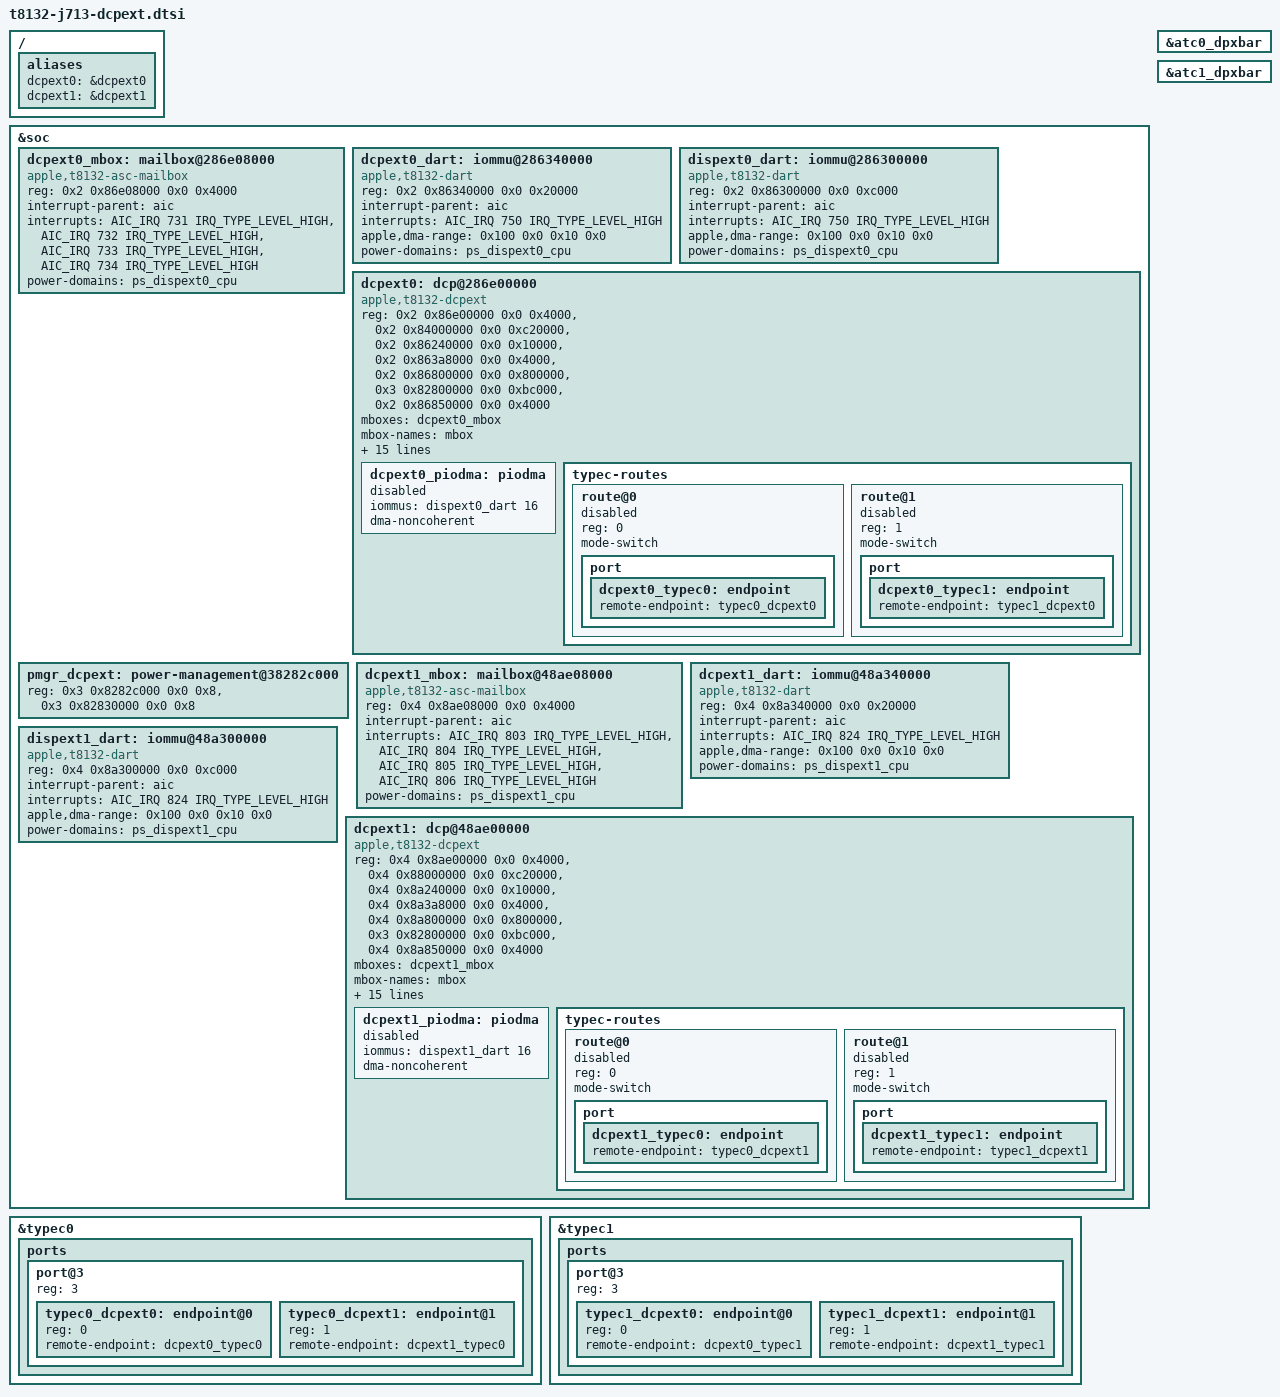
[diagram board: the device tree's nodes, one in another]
// SPDX-License-Identifier: GPL-2.0+ OR MIT
/*
 * Apple MacBook Air (13-inch, M4) external display coprocessors (DCP-ext).
 *
 * T8132 has two external display pipes, dispext0 and dispext1, each with
 * its own DCP, mailbox, DCP DART and display DART. They mirror the
 * internal display (t8132-j713-display.dtsi) at other bases and share its
 * firmware clock window (disp-4), which also holds their realtime bandwidth
 * request slots in the PMC.
 *
 * iBoot starts both and leaves them quiesced, as it does the internal one.
 * When the boot loader hands them over (opt-in, and only after the internal
 * display was handed over), it reserves their firmware memory, publishes
 * its UUID and version and marks each node
 * apple,t8132-dcpext-firmware-ready. The DCP driver adopts only a marked
 * coprocessor, and the DART driver leaves its firmware and display DARTs
 * untouched otherwise. PIODMA is enabled at runtime once the display DART
 * is adopted.
 *
 * Streams: SID23 for the firmware, SID0 scanout and SID16 PIODMA, as on
 * the internal display.
 *
 * Copyright The Asahi Linux Contributors
 */

/ {
	aliases {
		dcpext0 = &dcpext0;
		dcpext1 = &dcpext1;
	};
};

&soc {
	dcpext0_mbox: mailbox@286e08000 {
		compatible = "apple,t8132-asc-mailbox", "apple,asc-mailbox-v4";
		reg = <0x2 0x86e08000 0x0 0x4000>;
		interrupt-parent = <&aic>;
		interrupts = <AIC_IRQ 731 IRQ_TYPE_LEVEL_HIGH>,
			     <AIC_IRQ 732 IRQ_TYPE_LEVEL_HIGH>,
			     <AIC_IRQ 733 IRQ_TYPE_LEVEL_HIGH>,
			     <AIC_IRQ 734 IRQ_TYPE_LEVEL_HIGH>;
		interrupt-names = "send-empty", "send-not-empty",
				  "recv-empty", "recv-not-empty";
		power-domains = <&ps_dispext0_cpu>;
		#mbox-cells = <0>;
		status = "okay";
	};

	dcpext0_dart: iommu@286340000 {
		compatible = "apple,t8132-dart", "apple,t8110-dart";
		reg = <0x2 0x86340000 0x0 0x20000>;
		interrupt-parent = <&aic>;
		interrupts = <AIC_IRQ 750 IRQ_TYPE_LEVEL_HIGH>;
		#iommu-cells = <1>;
		apple,dma-range = <0x100 0x0 0x10 0x0>;
		power-domains = <&ps_dispext0_cpu>;
		status = "okay";
	};

	dispext0_dart: iommu@286300000 {
		compatible = "apple,t8132-dart", "apple,t8110-dart";
		reg = <0x2 0x86300000 0x0 0xc000>;
		interrupt-parent = <&aic>;
		interrupts = <AIC_IRQ 750 IRQ_TYPE_LEVEL_HIGH>;
		#iommu-cells = <1>;
		apple,dma-range = <0x100 0x0 0x10 0x0>;
		power-domains = <&ps_dispext0_cpu>;
		status = "okay";
	};

	dcpext0: dcp@286e00000 {
		compatible = "apple,t8132-dcpext";
		reg = <0x2 0x86e00000 0x0 0x4000>,
		      <0x2 0x84000000 0x0 0xc20000>,
		      <0x2 0x86240000 0x0 0x10000>,
		      <0x2 0x863a8000 0x0 0x4000>,
		      <0x2 0x86800000 0x0 0x800000>,
		      <0x3 0x82800000 0x0 0xbc000>,
		      <0x2 0x86850000 0x0 0x4000>;
		reg-names = "coproc", "disp-0", "disp-1", "disp-2", "disp-3",
			    "disp-4", "iop-vbar";
		mboxes = <&dcpext0_mbox>;
		mbox-names = "mbox";
		iommus = <&dcpext0_dart 23>;
		power-domains = <&ps_dispext0_cpu>;
		dma-noncoherent;
		apple,dcp-index = <1>;
		apple,bw-scratch = <&pmgr_dcpext 0 4 0>;
		status = "okay";

		dcpext0_piodma: piodma {
			iommus = <&dispext0_dart 16>;
			dma-noncoherent;
			status = "disabled";
		};
	};

	/*
	 * The external pipes' realtime bandwidth request slots in the PMC,
	 * 0x2c000 and 0x30000 into the window the dcpexts have as disp-4.
	 */
	pmgr_dcpext: power-management@38282c000 {
		reg = <0x3 0x8282c000 0x0 0x8>,
		      <0x3 0x82830000 0x0 0x8>;
		reg-names = "dcpext0-bw-scratch", "dcpext1-bw-scratch";
		#apple,bw-scratch-cells = <3>;
	};

	dcpext1_mbox: mailbox@48ae08000 {
		compatible = "apple,t8132-asc-mailbox", "apple,asc-mailbox-v4";
		reg = <0x4 0x8ae08000 0x0 0x4000>;
		interrupt-parent = <&aic>;
		interrupts = <AIC_IRQ 803 IRQ_TYPE_LEVEL_HIGH>,
			     <AIC_IRQ 804 IRQ_TYPE_LEVEL_HIGH>,
			     <AIC_IRQ 805 IRQ_TYPE_LEVEL_HIGH>,
			     <AIC_IRQ 806 IRQ_TYPE_LEVEL_HIGH>;
		interrupt-names = "send-empty", "send-not-empty",
				  "recv-empty", "recv-not-empty";
		power-domains = <&ps_dispext1_cpu>;
		#mbox-cells = <0>;
		status = "okay";
	};

	dcpext1_dart: iommu@48a340000 {
		compatible = "apple,t8132-dart", "apple,t8110-dart";
		reg = <0x4 0x8a340000 0x0 0x20000>;
		interrupt-parent = <&aic>;
		interrupts = <AIC_IRQ 824 IRQ_TYPE_LEVEL_HIGH>;
		#iommu-cells = <1>;
		apple,dma-range = <0x100 0x0 0x10 0x0>;
		power-domains = <&ps_dispext1_cpu>;
		status = "okay";
	};

	dispext1_dart: iommu@48a300000 {
		compatible = "apple,t8132-dart", "apple,t8110-dart";
		reg = <0x4 0x8a300000 0x0 0xc000>;
		interrupt-parent = <&aic>;
		interrupts = <AIC_IRQ 824 IRQ_TYPE_LEVEL_HIGH>;
		#iommu-cells = <1>;
		apple,dma-range = <0x100 0x0 0x10 0x0>;
		power-domains = <&ps_dispext1_cpu>;
		status = "okay";
	};

	dcpext1: dcp@48ae00000 {
		compatible = "apple,t8132-dcpext";
		reg = <0x4 0x8ae00000 0x0 0x4000>,
		      <0x4 0x88000000 0x0 0xc20000>,
		      <0x4 0x8a240000 0x0 0x10000>,
		      <0x4 0x8a3a8000 0x0 0x4000>,
		      <0x4 0x8a800000 0x0 0x800000>,
		      <0x3 0x82800000 0x0 0xbc000>,
		      <0x4 0x8a850000 0x0 0x4000>;
		reg-names = "coproc", "disp-0", "disp-1", "disp-2", "disp-3",
			    "disp-4", "iop-vbar";
		mboxes = <&dcpext1_mbox>;
		mbox-names = "mbox";
		iommus = <&dcpext1_dart 23>;
		power-domains = <&ps_dispext1_cpu>;
		dma-noncoherent;
		apple,dcp-index = <2>;
		apple,bw-scratch = <&pmgr_dcpext 1 4 0>;
		status = "okay";

		dcpext1_piodma: piodma {
			iommus = <&dispext1_dart 16>;
			dma-noncoherent;
			status = "disabled";
		};
	};
};

/*
 * The display crossbars of both ATCs, for the dcpexts' Type-C routes. Probe
 * touches no register; an output is only programmed once it is selected.
 */
&atc0_dpxbar {
	status = "okay";
};

&atc1_dpxbar {
	status = "okay";
};

/*
 * dcpext0's Type-C routes, UFP mux selector 2 on both ATC crossbars
 * (cells 0/1/2: DP PHY, DP IN0, DP IN1). The ATC PHYs have no DP alt mode:
 * the routes are for DisplayPort tunnels, and DP alt mode is refused. The
 * routes are disabled here; the display gate enables them only for a dcpext
 * the boot loader handed over, since a USB-C port controller waits for every
 * available route.
 */
&dcpext0 {
	apple,connector-type = "USB-C";
	phys = <&atcphy0 PHY_TYPE_DP>, <&atcphy1 PHY_TYPE_DP>;
	phy-names = "typec0", "typec1";
	mux-controls = <&atc0_dpxbar 0>, <&atc1_dpxbar 0>,
		       <&atc0_dpxbar 1>, <&atc0_dpxbar 2>,
		       <&atc1_dpxbar 1>, <&atc1_dpxbar 2>;
	mux-control-names = "typec0", "typec1",
			    "typec0-dpin0", "typec0-dpin1",
			    "typec1-dpin0", "typec1-dpin1";
	apple,typec-mux-indices = <2 2>;
	apple,typec-dptx-phys = <0 1>;

	typec-routes {
		#address-cells = <1>;
		#size-cells = <0>;

		route@0 {
			reg = <0>;
			mode-switch;
			status = "disabled";

			port {
				dcpext0_typec0: endpoint {
					remote-endpoint = <&typec0_dcpext0>;
				};
			};
		};

		route@1 {
			reg = <1>;
			mode-switch;
			status = "disabled";

			port {
				dcpext0_typec1: endpoint {
					remote-endpoint = <&typec1_dcpext0>;
				};
			};
		};
	};
};

/*
 * dcpext1's Type-C routes, UFP mux selector 4 on both ATC crossbars
 * (cells 0/1/2: DP PHY, DP IN0, DP IN1). The ATC PHYs have no DP alt mode:
 * the routes are for DisplayPort tunnels, and DP alt mode is refused. The
 * routes are disabled here; the display gate enables them only for a dcpext
 * the boot loader handed over, since a USB-C port controller waits for every
 * available route.
 */
&dcpext1 {
	apple,connector-type = "USB-C";
	phys = <&atcphy0 PHY_TYPE_DP>, <&atcphy1 PHY_TYPE_DP>;
	phy-names = "typec0", "typec1";
	mux-controls = <&atc0_dpxbar 0>, <&atc1_dpxbar 0>,
		       <&atc0_dpxbar 1>, <&atc0_dpxbar 2>,
		       <&atc1_dpxbar 1>, <&atc1_dpxbar 2>;
	mux-control-names = "typec0", "typec1",
			    "typec0-dpin0", "typec0-dpin1",
			    "typec1-dpin0", "typec1-dpin1";
	apple,typec-mux-indices = <4 4>;
	apple,typec-dptx-phys = <0 1>;

	typec-routes {
		#address-cells = <1>;
		#size-cells = <0>;

		route@0 {
			reg = <0>;
			mode-switch;
			status = "disabled";

			port {
				dcpext1_typec0: endpoint {
					remote-endpoint = <&typec0_dcpext1>;
				};
			};
		};

		route@1 {
			reg = <1>;
			mode-switch;
			status = "disabled";

			port {
				dcpext1_typec1: endpoint {
					remote-endpoint = <&typec1_dcpext1>;
				};
			};
		};
	};
};

&typec0 {
	ports {
		port@3 {
			reg = <3>;
			#address-cells = <1>;
			#size-cells = <0>;

			typec0_dcpext0: endpoint@0 {
				reg = <0>;
				remote-endpoint = <&dcpext0_typec0>;
			};

			typec0_dcpext1: endpoint@1 {
				reg = <1>;
				remote-endpoint = <&dcpext1_typec0>;
			};
		};
	};
};

&typec1 {
	ports {
		port@3 {
			reg = <3>;
			#address-cells = <1>;
			#size-cells = <0>;

			typec1_dcpext0: endpoint@0 {
				reg = <0>;
				remote-endpoint = <&dcpext0_typec1>;
			};

			typec1_dcpext1: endpoint@1 {
				reg = <1>;
				remote-endpoint = <&dcpext1_typec1>;
			};
		};
	};
};
